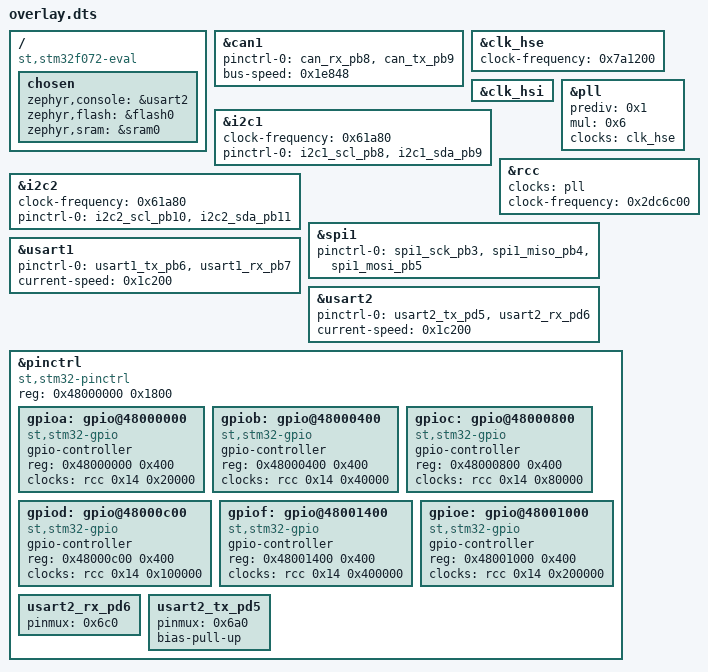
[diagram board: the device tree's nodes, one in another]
/ {
	compatible = "st,stm32f072-eval";
	chosen {
		zephyr,console = &usart2;
		zephyr,flash = &flash0;
		zephyr,sram = &sram0;
	};
};
&can1{
	status = "okay";
	pinctrl-0 = < &can_rx_pb8 &can_tx_pb9 >;
	pinctrl-names = "default";
	bus-speed = < 0x1e848 >;
};
&clk_hse{
	status = "okay";
	clock-frequency = < 0x7a1200 >;
};
&clk_hsi{
	status = "okay";
};
&i2c1{
	clock-frequency = < 0x61a80 >;
	status = "okay";
	pinctrl-0 = < &i2c1_scl_pb8 &i2c1_sda_pb9 >;
	pinctrl-names = "default";
};
&i2c2{
	clock-frequency = < 0x61a80 >;
	status = "okay";
	pinctrl-0 = < &i2c2_scl_pb10 &i2c2_sda_pb11 >;
	pinctrl-names = "default";
};
&pll{
	status = "okay";
	prediv = < 0x1 >;
	mul = < 0x6 >;
	clocks = < &clk_hse >;
};
&rcc{
	clocks = < &pll >;
	clock-frequency = < 0x2dc6c00 >;
};
&spi1{
	status = "okay";
	pinctrl-0 = < &spi1_sck_pb3 &spi1_miso_pb4 &spi1_mosi_pb5 >;
	pinctrl-names = "default";
};
&usart1{
	status = "okay";
	pinctrl-0 = < &usart1_tx_pb6 &usart1_rx_pb7 >;
	pinctrl-names = "default";
	current-speed = < 0x1c200 >;
};
&usart2{
	status = "okay";
	pinctrl-0 = < &usart2_tx_pd5 &usart2_rx_pd6 >;
	pinctrl-names = "default";
	current-speed = < 0x1c200 >;
};
&pinctrl{
	compatible = "st,stm32-pinctrl";
	#address-cells = < 0x1 >;
	#size-cells = < 0x1 >;
	reg = < 0x48000000 0x1800 >;
	gpioa: gpio@48000000 {
		compatible = "st,stm32-gpio";
		gpio-controller;
		#gpio-cells = < 0x2 >;
		reg = < 0x48000000 0x400 >;
		clocks = < &rcc 0x14 0x20000 >;
	};
	gpiob: gpio@48000400 {
		compatible = "st,stm32-gpio";
		gpio-controller;
		#gpio-cells = < 0x2 >;
		reg = < 0x48000400 0x400 >;
		clocks = < &rcc 0x14 0x40000 >;
	};
	gpioc: gpio@48000800 {
		compatible = "st,stm32-gpio";
		gpio-controller;
		#gpio-cells = < 0x2 >;
		reg = < 0x48000800 0x400 >;
		clocks = < &rcc 0x14 0x80000 >;
	};
	gpiod: gpio@48000c00 {
		compatible = "st,stm32-gpio";
		gpio-controller;
		#gpio-cells = < 0x2 >;
		reg = < 0x48000c00 0x400 >;
		clocks = < &rcc 0x14 0x100000 >;
	};
	gpiof: gpio@48001400 {
		compatible = "st,stm32-gpio";
		gpio-controller;
		#gpio-cells = < 0x2 >;
		reg = < 0x48001400 0x400 >;
		clocks = < &rcc 0x14 0x400000 >;
	};
	gpioe: gpio@48001000 {
		compatible = "st,stm32-gpio";
		gpio-controller;
		#gpio-cells = < 0x2 >;
		reg = < 0x48001000 0x400 >;
		clocks = < &rcc 0x14 0x200000 >;
	};
	usart2_rx_pd6: usart2_rx_pd6 {
		pinmux = < 0x6c0 >;
	};
	usart2_tx_pd5: usart2_tx_pd5 {
		pinmux = < 0x6a0 >;
		bias-pull-up;
	};
};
